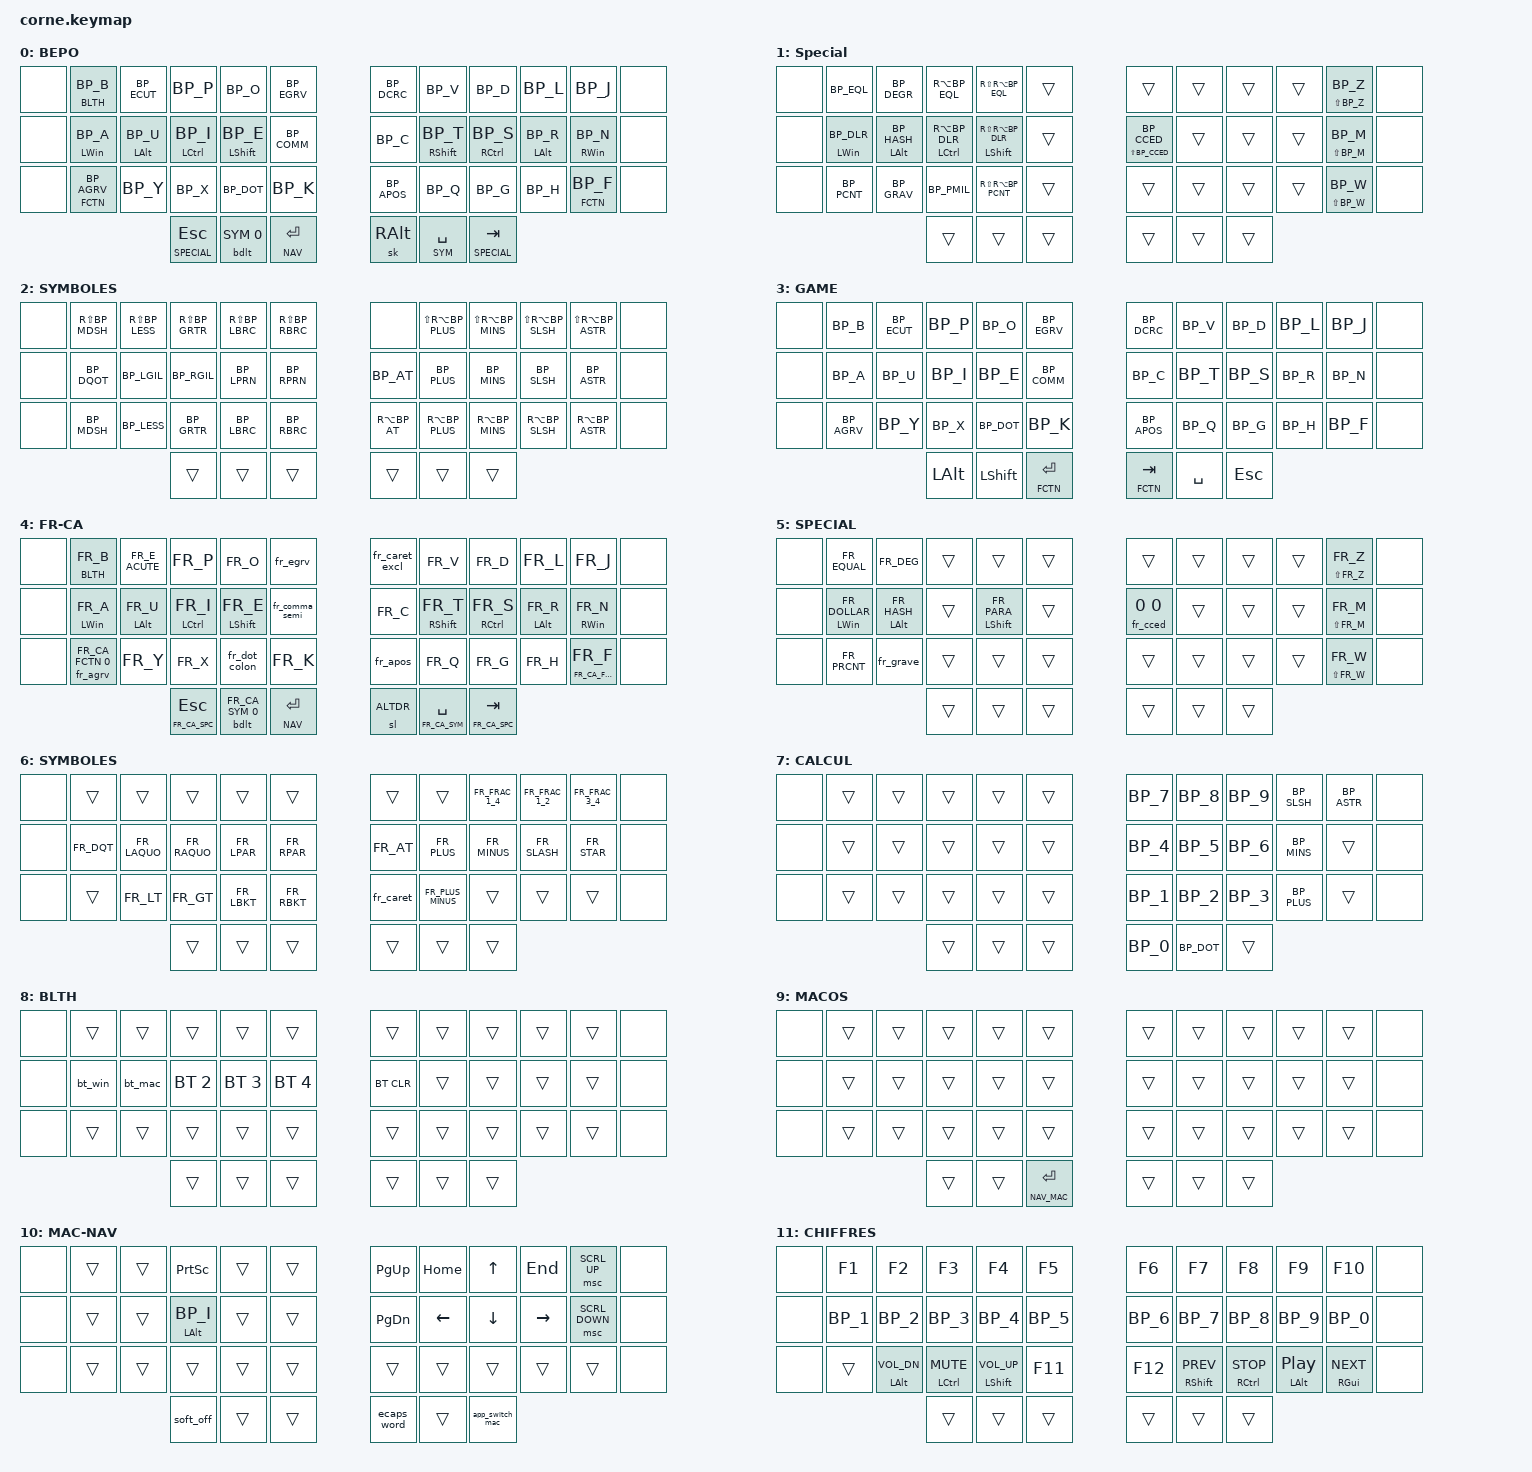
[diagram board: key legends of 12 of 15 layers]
/*
 * Corne 36-touches — ZMK — portage du layout BÉPO
 *
 *  ┌────┬────┬────┬────┬────┬────┐         ┌────┬────┬────┬────┬────┬────┐
 *  │ 0  │ 1  │ 2  │ 3  │ 4  │ 5  │         │ 6  │ 7  │ 8  │ 9  │ 10 │ 11 │
 *  ├────┼────┼────┼────┼────┼────┤         ├────┼────┼────┼────┼────┼────┤
 *  │ 12 │ 13 │ 14 │ 15 │ 16 │ 17 │         │ 18 │ 19 │ 20 │ 21 │ 22 │ 23 │
 *  ├────┼────┼────┼────┼────┼────┤         ├────┼────┼────┼────┼────┼────┤
 *  │ 24 │ 25 │ 26 │ 27 │ 28 │ 29 │         │ 30 │ 31 │ 32 │ 33 │ 34 │ 35 │
 *  └────┴────┴────┴─┬──┴─┬──┴─┬──┴─┐     ┌─┴──┬─┴──┬─┴──┬─┴────┴────┴────┘
 *                   │ 36 │ 37 │ 38 │     │ 39 │ 40 │ 41 │
 *                   └────┴────┴────┘     └────┴────┴────┘
 */

#include <behaviors.dtsi>
#include <dt-bindings/zmk/keys.h>
#include <dt-bindings/zmk/bt.h>
#include <dt-bindings/zmk/outputs.h>
#include <dt-bindings/zmk/pointing.h>
#include "keys_fr_csa.h"

/* ============================================================
 * LAYER NUMBERS
 * ============================================================ */
#define BEPO        0
#define SPECIAL     1
#define SYM         2
#define GAME        3
#define FR_CA       4
#define FR_CA_SPC   5
#define FR_CA_SYM   6
#define NUMPAD      7
#define BLTH        8
#define MACOS       9
#define NAV_MAC    10
#define FCTN       11
#define NAV        12
#define ALTDR      13
#define FR_CA_FCTN 14

/* ============================================================
 * BÉPO 
 * ============================================================ */
#define BP_B        Q
#define BP_ECUT     W
#define BP_W        RBKT
#define BP_P        E
#define BP_O        R
#define BP_EGRV     T
#define BP_A        A
#define BP_U        S
#define BP_I        D
#define BP_E        F
#define BP_COMM     G
#define BP_AGRV     Z
#define BP_Y        X
#define BP_X        C
#define BP_DOT      V
#define BP_K        B
#define BP_DCRC     Y
#define BP_V        U
#define BP_M        APOS
#define BP_D        I
#define BP_L        O
#define BP_J        P
#define BP_Z        LBKT
#define BP_C        H
#define BP_CCED     BACKSLASH
#define BP_T        J
#define BP_S        K
#define BP_R        L
#define BP_N        SEMI
#define BP_APOS     N
#define BP_Q        M
#define BP_G        COMMA
#define BP_H        DOT
#define BP_F        FSLH
#define BP_DQOT     N1
#define BP_DLR      GRAVE
#define BP_LGIL     N2
#define BP_RGIL     N3
#define BP_LPRN     N4
#define BP_RPRN     N5
#define BP_1        LS(N1)
#define BP_HASH     LS(GRAVE)
#define BP_2        LS(N2)
#define BP_3        LS(N3)
#define BP_4        LS(N4)
#define BP_5        LS(N5)
#define BP_MDSH     RA(N1)
#define BP_LESS     RA(N2)
#define BP_GRTR     RA(N3)
#define BP_LBRC     RA(N4)
#define BP_RBRC     RA(N5)
#define BP_AT       N6
#define BP_PLUS     N7
#define BP_MINS     N8
#define BP_SLSH     N9
#define BP_ASTR     N0
#define BP_EQL      MINUS
#define BP_6        LS(N6)
#define BP_7        LS(N7)
#define BP_8        LS(N8)
#define BP_9        LS(N9)
#define BP_0        LS(N0)
#define BP_DEGR     LS(MINUS)
#define BP_PCNT     EQUAL
#define BP_PMIL     RA(EQUAL)
#define BP_GRAV     LS(EQUAL)

#include "behaviors.dtsi"
#include "combos.dtsi"
#include "macros.dtsi"

/ {
    keymap {
        compatible = "zmk,keymap";

        layer_bepo { // Layer 0
                display-name = "BEPO";
        //  ┌──────────────────┬──────────────────┬──────────────────┬──────────────────┬──────────────────┬──────────────────┐                  ┌──────────────────┬──────────────────┬──────────────────┬──────────────────┬──────────────────┬──────────────────┐
        //  │                  │ B           BLTH │ É                │ P                │ O                │ È                │                  │ ^                │ V                │ D                │ L                │ J                │                  │
        //  ├──────────────────┼──────────────────┼──────────────────┼──────────────────┼──────────────────┼──────────────────┤                  ├──────────────────┼──────────────────┼──────────────────┼──────────────────┼──────────────────┼──────────────────┤
        //  │                  │ A           LWIN │ U           LALT │ I          LCTRL │ E         LSHIFT │ ,                │                  │ C                │ T         RSHIFT │ S          RCTRL │ R           LALT │ N           RWIN │                  │
        //  ├──────────────────┼──────────────────┼──────────────────┼──────────────────┼──────────────────┼──────────────────┤                  ├──────────────────┼──────────────────┼──────────────────┼──────────────────┼──────────────────┼──────────────────┤
        //  │                  │ À           FCTN │ Y                │ X                │ .                │ K                │                  │ ’                │ Q                │ G                │ H                │ F           FCTN │                  │
        //  └──────────────────┴──────────────────┴──────────────────┼──────────────────┼──────────────────┼──────────────────┤                  ├──────────────────┼──────────────────┼──────────────────┼──────────────────┴──────────────────┴──────────────────┘
        //                                                           │ ESC      SPECIAL │ BSPC         SYM │ ENTER        NAV │                  │ OSM RALT         │ SPACE        SYM │ TAB      SPECIAL │
        //                                                           └──────────────────┴──────────────────┴──────────────────┘                  └──────────────────┴──────────────────┴──────────────────┘
            bindings = <
                &none           &lt  BLTH  BP_B     &kp  BP_ECUT       &kp  BP_P         &kp   BP_O          &kp BP_EGRV                          &kp BP_DCRC         &kp  BP_V          &kp  BP_D          &kp  BP_L          &kp  BP_J          &none
                &none           &hml LWIN  BP_A     &hml LALT BP_U     &hml LCTRL BP_I   &hml  LSHFT  BP_E   &kp BP_COMM                          &kp BP_C            &hmr RSHFT BP_T    &hmr RCTRL BP_S    &hmr LALT BP_R     &hmr RWIN BP_N     &none
                &none           &lt  FCTN  BP_AGRV  &kp  BP_Y          &kp  BP_X         &kp   BP_DOT        &kp BP_K                             &kp BP_APOS         &kp  BP_Q          &kp  BP_G          &kp  BP_H          &lt  FCTN BP_F     &none
                                                                       &lt2 SPECIAL ESC    &bdlt SYM 0       &lt NAV ENTER                        &sk RALT            &lt  SYM   SPACE   &lt2 SPECIAL TAB
            >;
        };

        layer_special { // Layer 1
                display-name = "Special";
        //  ┌──────────────────┬──────────────────┬──────────────────┬──────────────────┬──────────────────┬──────────────────┐                  ┌──────────────────┬──────────────────┬──────────────────┬──────────────────┬──────────────────┬──────────────────┐
        //  │                  │ =                │ °                │ ≠                │ ′                │                  │                  │                  │                  │                  │                  │ Z                │                  │
        //  ├──────────────────┼──────────────────┼──────────────────┼──────────────────┼──────────────────┼──────────────────┤                  ├──────────────────┼──────────────────┼──────────────────┼──────────────────┼──────────────────┼──────────────────┤
        //  │                  │ $           LWIN │ #           LALT │ –          LCTRL │ ¶         LSHIFT │                  │                  │ Ç                │                  │                  │                  │ M                │                  │
        //  ├──────────────────┼──────────────────┼──────────────────┼──────────────────┼──────────────────┼──────────────────┤                  ├──────────────────┼──────────────────┼──────────────────┼──────────────────┼──────────────────┼──────────────────┤
        //  │                  │ %                │ `                │ ‰                │ ″                │                  │                  │                  │                  │                  │                  │ W                │                  │
        //  └──────────────────┴──────────────────┴──────────────────┼──────────────────┼──────────────────┼──────────────────┤                  ├──────────────────┼──────────────────┼──────────────────┼──────────────────┴──────────────────┴──────────────────┘
        //                                                           │                  │                  │                  │                  │                  │                  │                  │
        //                                                           └──────────────────┴──────────────────┴──────────────────┘                  └──────────────────┴──────────────────┴──────────────────┘
           bindings = <
                &none           &kp  BP_EQL          &kp  BP_DEGR      &kp RA(BP_EQL)        &kp  RS(RA(BP_EQL))        &trans                      &trans                   &trans      &trans             &trans             &mt LS(BP_Z) BP_Z  &none 
                &none           &hml LWIN BP_DLR     &hml LALT BP_HASH &hml LCTRL RA(BP_DLR) &hml LSHIFT RS(RA(BP_DLR)) &trans                      &mt LS(BP_CCED) BP_CCED  &trans      &trans             &trans             &mt LS(BP_M) BP_M  &none 
                &none           &kp  BP_PCNT         &kp  BP_GRAV      &kp BP_PMIL           &kp  RS(RA(BP_PCNT))       &trans                      &trans                   &trans      &trans             &trans             &mt LS(BP_W) BP_W  &none 
                                                                       &trans                &trans                     &trans                      &trans                   &trans      &trans
            >;

        };
        layer_sym { // Layer 2
                display-name = "SYMBOLES";
        //  ┌──────────────────┬──────────────────┬──────────────────┬──────────────────┬──────────────────┬──────────────────┐                  ┌──────────────────┬──────────────────┬──────────────────┬──────────────────┬──────────────────┬──────────────────┐
        //  │                  │ „                │ “                │ ”                │ ⩽                │ ⩾               │                  │                  │                  │ ¼                │ ½                │ ¾                │                  │
        //  ├──────────────────┼──────────────────┼──────────────────┼──────────────────┼──────────────────┼──────────────────┤                  ├──────────────────┼──────────────────┼──────────────────┼──────────────────┼──────────────────┼──────────────────┤
        //  │                  │ "                │ «                │ »                │ (                │ )                │                  │ @                │ +                │ -                │ /                │ *                │                  │                  │
        //  ├──────────────────┼──────────────────┼──────────────────┼──────────────────┼──────────────────┼──────────────────┤                  ├──────────────────┼──────────────────┼──────────────────┼──────────────────┼──────────────────┼──────────────────┤
        //  │                  │ —                │ <                │ >                │ [                │ ]                │                  │ ^                │ ±                │ −                │ ÷                │ ×                │                  │
        //  └──────────────────┴──────────────────┴──────────────────┼──────────────────┼──────────────────┼──────────────────┤                  ├──────────────────┼──────────────────┼──────────────────┼──────────────────┴──────────────────┴──────────────────┘
        //                                                           │                  │                  │                  │                  │                  │                  │                  │
        //                                                           └──────────────────┴──────────────────┴──────────────────┘                  └──────────────────┴──────────────────┴──────────────────┘
            bindings = <
                &none           &kp RS(BP_MDSH)     &kp RS(BP_LESS)   &kp RS(BP_GRTR)  &kp RS(BP_LBRC)    &kp RS(BP_RBRC)                          &none              &kp LS(RA(BP_PLUS)) &kp LS(RA(BP_MINS)) &kp LS(RA(BP_SLSH)) &kp LS(RA(BP_ASTR)) &none
                &none           &kp BP_DQOT         &kp BP_LGIL       &kp BP_RGIL      &kp BP_LPRN        &kp BP_RPRN                              &kp BP_AT          &kp BP_PLUS         &kp BP_MINS         &kp BP_SLSH         &kp BP_ASTR         &none
                &none           &kp BP_MDSH         &kp BP_LESS       &kp BP_GRTR      &kp BP_LBRC        &kp BP_RBRC                              &kp RA(BP_AT)      &kp RA(BP_PLUS)     &kp RA(BP_MINS)     &kp RA(BP_SLSH)     &kp RA(BP_ASTR)     &none
                                                                      &trans           &trans             &trans                                   &trans             &trans              &trans
            >;
        };

        layer_game { // Layer 3
                display-name = "GAME";
        //  ┌──────────────────┬──────────────────┬──────────────────┬──────────────────┬──────────────────┬──────────────────┐                  ┌──────────────────┬──────────────────┬──────────────────┬──────────────────┬──────────────────┬──────────────────┐
        //  │                  │ B                │ É                │ P                │ O                │ È                │                  │ ^                │ V                │ D                │ L                │ J                │                  │
        //  ├──────────────────┼──────────────────┼──────────────────┼──────────────────┼──────────────────┼──────────────────┤                  ├──────────────────┼──────────────────┼──────────────────┼──────────────────┼──────────────────┼──────────────────┤
        //  │                  │ A                │ U                │ I                │ E                │ ,                │                  │ C                │ T                │ S                │ R                │ N                │                  │
        //  ├──────────────────┼──────────────────┼──────────────────┼──────────────────┼──────────────────┼──────────────────┤                  ├──────────────────┼──────────────────┼──────────────────┼──────────────────┼──────────────────┼──────────────────┤
        //  │                  │ À                │ Y                │ X                │ .                │ K                │                  │ ’                │ Q                │ G                │ H                │ F                │                  │
        //  └──────────────────┴──────────────────┴──────────────────┼──────────────────┼──────────────────┼──────────────────┤                  ├──────────────────┼──────────────────┼──────────────────┼──────────────────┴──────────────────┴──────────────────┘
        //                                                           │ ESC              │ LSHIFT           │ ENTER            │                  │                  │                  │                  │
        //                                                           └──────────────────┴──────────────────┴──────────────────┘                  └──────────────────┴──────────────────┴──────────────────┘
            bindings = <
                &none           &kp  BP_B           &kp  BP_ECUT       &kp  BP_P         &kp  BP_O          &kp BP_EGRV                          &kp BP_DCRC         &kp  BP_V          &kp  BP_D          &kp  BP_L          &kp  BP_J          &none
                &none           &kp  BP_A           &kp  BP_U          &kp  BP_I         &kp  BP_E          &kp BP_COMM                          &kp BP_C            &kp  BP_T          &kp  BP_S          &kp  BP_R          &kp  BP_N          &none
                &none           &kp  BP_AGRV        &kp  BP_Y          &kp  BP_X         &kp  BP_DOT        &kp BP_K                             &kp BP_APOS         &kp  BP_Q          &kp  BP_G          &kp  BP_H          &kp  BP_F          &none
                                                                       &kp  LALT         &kp  LSHIFT        &lt FCTN ENTER                       &lt FCTN TAB        &kp  SPACE         &kp  ESC
            >;

        };

        layer_fr_ca { // Layer 4
                display-name = "FR-CA";
        //  ┌──────────────────┬──────────────────┬──────────────────┬──────────────────┬──────────────────┬──────────────────┐                  ┌──────────────────┬──────────────────┬──────────────────┬──────────────────┬──────────────────┬──────────────────┐
        //  │                  │ B           BLTH │ É                │ P                │ O                │ È                │                  │ ^                │ V                │ D                │ L                │ J                │                  │
        //  ├──────────────────┼──────────────────┼──────────────────┼──────────────────┼──────────────────┼──────────────────┤                  ├──────────────────┼──────────────────┼──────────────────┼──────────────────┼──────────────────┼──────────────────┤
        //  │                  │ A           LWIN │ U           LALT │ I          LCTRL │ E         LSHIFT │ ,                │                  │ C                │ T         RSHIFT │ S          RCTRL │ R           LALT │ N           RWIN │                  │
        //  ├──────────────────┼──────────────────┼──────────────────┼──────────────────┼──────────────────┼──────────────────┤                  ├──────────────────┼──────────────────┼──────────────────┼──────────────────┼──────────────────┼──────────────────┤
        //  │                  │ À           FCTN │ Y                │ X                │ .                │ K                │                  │ ’                │ Q                │ G                │ H                │ F           FCTN │                  │
        //  └──────────────────┴──────────────────┴──────────────────┼──────────────────┼──────────────────┼──────────────────┤                  ├──────────────────┼──────────────────┼──────────────────┼──────────────────┴──────────────────┴──────────────────┘
        //                                                           │ ESC    FR_CA_SPC │ BSPC         SYM │ ENTER        NAV │                  │ OSM RALT         │ SPACE        SYM │ TAB    FR_CA_SPC │
        //                                                           └──────────────────┴──────────────────┴──────────────────┘                  └──────────────────┴──────────────────┴──────────────────┘
            bindings = <
                &none           &lt  BLTH  FR_B     &kp  FR_E_ACUTE    &kp  FR_P            &kp  FR_O          &fr_egrv                           &fr_caret_excl     &kp  FR_V           &kp  FR_D          &kp  FR_L          &kp  FR_J           &none
                &none           &hml LWIN  FR_A     &hml LALT  FR_U    &hml LCTRL   FR_I    &hml LSHFT FR_E    &fr_comma_semi                     &kp  FR_C          &hmr RSHFT FR_T     &hmr RCTRL   FR_S  &hmr LALT  FR_R    &hmr RWIN  FR_N     &none
                &none           &fr_agrv FR_CA_FCTN 0 &kp  FR_Y       &kp  FR_X            &fr_dot_colon      &kp FR_K                           &fr_apos           &kp  FR_Q           &kp  FR_G          &kp  FR_H          &lt FR_CA_FCTN FR_F &none
                                                                       &lt2 FR_CA_SPC ESC   &bdlt FR_CA_SYM 0  &lt NAV ENTER                      &sl  ALTDR         &lt FR_CA_SYM SPACE &lt2 FR_CA_SPC TAB
            >;
        }; 

        layer_fr_ca_special { // Layer 5
                display-name = "SPECIAL";
        //  ┌──────────────────┬──────────────────┬──────────────────┬──────────────────┬──────────────────┬──────────────────┐                  ┌──────────────────┬──────────────────┬──────────────────┬──────────────────┬──────────────────┬──────────────────┐
        //  │                  │ =                │ °                │                  │                  │                  │                  │                  │                  │                  │                  │ Z                │                  │
        //  ├──────────────────┼──────────────────┼──────────────────┼──────────────────┼──────────────────┼──────────────────┤                  ├──────────────────┼──────────────────┼──────────────────┼──────────────────┼──────────────────┼──────────────────┤
        //  │                  │ $           LWIN │ #           LALT │                  │ ¶          LSHFT │                  │                  │ Ç                │                  │                  │                  │ M                │                  │
        //  ├──────────────────┼──────────────────┼──────────────────┼──────────────────┼──────────────────┼──────────────────┤                  ├──────────────────┼──────────────────┼──────────────────┼──────────────────┼──────────────────┼──────────────────┤
        //  │                  │ %                │ `                │                  │                  │                  │                  │                  │                  │                  │                  │ W                │                  │
        //  └──────────────────┴──────────────────┴──────────────────┼──────────────────┼──────────────────┼──────────────────┤                  ├──────────────────┼──────────────────┼──────────────────┼──────────────────┴──────────────────┴──────────────────┘
        //                                                           │                  │                  │                  │                  │                  │                  │                  │
        //                                                           └──────────────────┴──────────────────┴──────────────────┘                  └──────────────────┴──────────────────┴──────────────────┘
           bindings = <
                &none           &kp  FR_EQUAL        &kp  FR_DEG        &trans            &trans               &trans                             &trans                &trans             &trans             &trans             &mt LS(FR_Z) FR_Z   &none 
                &none           &hml LWIN FR_DOLLAR  &hml LALT FR_HASH  &trans            &hml LSHIFT FR_PARA  &trans                             &fr_cced 0 0          &trans             &trans             &trans             &mt LS(FR_M) FR_M   &none
                &none           &kp  FR_PRCNT        &fr_grave          &trans            &trans               &trans                             &trans                &trans             &trans             &trans             &mt LS(FR_W) FR_W   &none 
                                                                        &trans            &trans               &trans                             &trans                &trans             &trans
            >;
        };

        layer_fr_ca_sym { // Layer 6
                display-name = "SYMBOLES";
        //  ┌──────────────────┬──────────────────┬──────────────────┬──────────────────┬──────────────────┬──────────────────┐                  ┌──────────────────┬──────────────────┬──────────────────┬──────────────────┬──────────────────┬──────────────────┐
        //  │                  │                  │                  │                  │                  │                  │                  │                  │                  │ ¼                │ ½                │ ¾                │                  │
        //  ├──────────────────┼──────────────────┼──────────────────┼──────────────────┼──────────────────┼──────────────────┤                  ├──────────────────┼──────────────────┼──────────────────┼──────────────────┼──────────────────┼──────────────────┤
        //  │                  │ "                │ «                │ »                │ (                │ )                │                  │ @                │ +                │ -                │ /                │ *                │                  │                  │
        //  ├──────────────────┼──────────────────┼──────────────────┼──────────────────┼──────────────────┼──────────────────┤                  ├──────────────────┼──────────────────┼──────────────────┼──────────────────┼──────────────────┼──────────────────┤
        //  │                  │                  │ <                │ >                │ [                │ ]                │                  │ ^                │ ±                │                  │                  │                  │                  │
        //  └──────────────────┴──────────────────┴──────────────────┼──────────────────┼──────────────────┼──────────────────┤                  ├──────────────────┼──────────────────┼──────────────────┼──────────────────┴──────────────────┴──────────────────┘
        //                                                           │                  │                  │                  │                  │                  │                  │                  │
        //                                                           └──────────────────┴──────────────────┴──────────────────┘                  └──────────────────┴──────────────────┴──────────────────┘
            bindings = <
                &none           &trans              &trans            &trans           &trans             &trans                                   &trans             &trans              &kp FR_FRAC_1_4     &kp FR_FRAC_1_2     &kp FR_FRAC_3_4     &none
                &none           &kp FR_DQT          &kp FR_LAQUO      &kp FR_RAQUO     &kp FR_LPAR        &kp FR_RPAR                              &kp FR_AT          &kp FR_PLUS         &kp FR_MINUS        &kp FR_SLASH        &kp FR_STAR         &none
                &none           &trans              &kp FR_LT         &kp FR_GT        &kp FR_LBKT        &kp FR_RBKT                              &fr_caret          &kp FR_PLUS_MINUS   &trans              &trans              &trans              &none
                                                                      &trans           &trans             &trans                                   &trans             &trans              &trans
            >;
        };

        layer_numpad { // Layer 7
                display-name = "CALCUL";
        //  ┌──────────────────┬──────────────────┬──────────────────┬──────────────────┬──────────────────┬──────────────────┐                  ┌──────────────────┬──────────────────┬──────────────────┬──────────────────┬──────────────────┬──────────────────┐
        //  │                  │                  │                  │                  │                  │                  │                  │ 7                │ 8                │ 9                │ /                │ *                │                  │
        //  ├──────────────────┼──────────────────┼──────────────────┼──────────────────┼──────────────────┼──────────────────┤                  ├──────────────────┼──────────────────┼──────────────────┼──────────────────┼──────────────────┼──────────────────┤
        //  │                  │                  │                  │                  │                  │                  │                  │ 4                │ 5                │ 6                │ -                │                  │                  │
        //  ├──────────────────┼──────────────────┼──────────────────┼──────────────────┼──────────────────┼──────────────────┤                  ├──────────────────┼──────────────────┼──────────────────┼──────────────────┼──────────────────┼──────────────────┤
        //  │                  │                  │                  │                  │                  │                  │                  │ 1                │ 2                │ 3                │ +                │                  │                  │
        //  └──────────────────┴──────────────────┴──────────────────┼──────────────────┼──────────────────┼──────────────────┤                  ├──────────────────┼──────────────────┼──────────────────┼──────────────────┴──────────────────┴──────────────────┘
        //                                                           │                  │                  │                  │                  │ 0                │ .                │                  │
        //                                                           └──────────────────┴──────────────────┴──────────────────┘                  └──────────────────┴──────────────────┴──────────────────┘
           bindings = <
                &none           &trans                    &trans            &trans           &trans             &trans                            &kp BP_7            &kp BP_8           &kp BP_9           &kp BP_SLSH        &kp BP_ASTR        &none
                &none           &trans                    &trans            &trans           &trans             &trans                            &kp BP_4            &kp BP_5           &kp BP_6           &kp BP_MINS        &trans             &none
                &none           &trans                    &trans            &trans           &trans             &trans                            &kp BP_1            &kp BP_2           &kp BP_3           &kp BP_PLUS        &trans             &none
                                                                            &trans           &trans             &trans                            &kp BP_0            &kp BP_DOT         &trans
            >;
        };
        
        layer_bluetooth { // Layer 8
                display-name = "BLTH";
        //  ┌──────────────────┬──────────────────┬──────────────────┬──────────────────┬──────────────────┬──────────────────┐                  ┌──────────────────┬──────────────────┬──────────────────┬──────────────────┬──────────────────┬──────────────────┐
        //  │                  │                  │                  │                  │                  │                  │                  │                  │                  │                  │                  │                  │                  │
        //  ├──────────────────┼──────────────────┼──────────────────┼──────────────────┼──────────────────┼──────────────────┤                  ├──────────────────┼──────────────────┼──────────────────┼──────────────────┼──────────────────┼──────────────────┤
        //  │                  │ CHANNEL 0        │ CHANNEL 1        │ CHANNEL 2        │ CHANNEL 3        │ CHANNEL 4        │                  │ BT_CLR           │                  │                  │                  │                  │                  │
        //  ├──────────────────┼──────────────────┼──────────────────┼──────────────────┼──────────────────┼──────────────────┤                  ├──────────────────┼──────────────────┼──────────────────┼──────────────────┼──────────────────┼──────────────────┤
        //  │                  │                  │                  │                  │                  │                  │                  │                  │                  │                  │                  │                  │                  │
        //  └──────────────────┴──────────────────┴──────────────────┼──────────────────┼──────────────────┼──────────────────┤                  ├──────────────────┼──────────────────┼──────────────────┼──────────────────┴──────────────────┴──────────────────┘
        //                                                           │                  │                  │                  │                  │                  │                  │                  │
        //                                                           └──────────────────┴──────────────────┴──────────────────┘                  └──────────────────┴──────────────────┴──────────────────┘
           bindings = <
                &none           &trans                    &trans            &trans           &trans             &trans                          &trans                      &trans            &trans           &trans          &trans    &none 
                &none           &bt_win                   &bt_mac           &bt BT_SEL 2     &bt BT_SEL 3       &bt BT_SEL 4                    &bt BT_CLR                  &trans            &trans           &trans          &trans    &none 
                &none           &trans                    &trans            &trans           &trans             &trans                          &trans                      &trans            &trans           &trans          &trans    &none 
                                                                            &trans           &trans             &trans                          &trans                      &trans            &trans
            >;
        };

        layer_mac_os { // Layer 9
                display-name = "MACOS";
        //  ┌──────────────────┬──────────────────┬──────────────────┬──────────────────┬──────────────────┬──────────────────┐                  ┌──────────────────┬──────────────────┬──────────────────┬──────────────────┬──────────────────┬──────────────────┐
        //  │                  │                  │                  │                  │                  │                  │                  │                  │                  │                  │                  │                  │                  │
        //  ├──────────────────┼──────────────────┼──────────────────┼──────────────────┼──────────────────┼──────────────────┤                  ├──────────────────┼──────────────────┼──────────────────┼──────────────────┼──────────────────┼──────────────────┤
        //  │                  │                  │                  │                  │                  │                  │                  │                  │                  │                  │                  │                  │                  │
        //  ├──────────────────┼──────────────────┼──────────────────┼──────────────────┼──────────────────┼──────────────────┤                  ├──────────────────┼──────────────────┼──────────────────┼──────────────────┼──────────────────┼──────────────────┤
        //  │                  │                  │                  │                  │                  │                  │                  │                  │                  │                  │                  │                  │                  │
        //  └──────────────────┴──────────────────┴──────────────────┼──────────────────┼──────────────────┼──────────────────┤                  ├──────────────────┼──────────────────┼──────────────────┼──────────────────┴──────────────────┴──────────────────┘
        //                                                           │                  │                  │ ENTER    NAV_MAC │                  │                  │                  │                  │
        //                                                           └──────────────────┴──────────────────┴──────────────────┘                  └──────────────────┴──────────────────┴──────────────────┘
            bindings = <
                &none           &trans                    &trans            &trans          &trans             &trans                              &trans              &trans            &trans           &trans          &trans    &none 
                &none           &trans                    &trans            &trans          &trans             &trans                              &trans              &trans            &trans           &trans          &trans    &none 
                &none           &trans                    &trans            &trans          &trans             &trans                              &trans              &trans            &trans           &trans          &trans    &none 
                                                                            &trans          &trans             &lt NAV_MAC ENTER                   &trans              &trans            &trans
            >;
        };

        layer_nav_mac { // Layer 10
                display-name = "MAC-NAV";
        //  ┌──────────────────┬──────────────────┬──────────────────┬──────────────────┬──────────────────┬──────────────────┐                  ┌──────────────────┬──────────────────┬──────────────────┬──────────────────┬──────────────────┬──────────────────┐
        //  │                  │                  │                  │ PRINTSCREEN      │                  │                  │                  │ PGUP             │ HOME             │ UP               │ END              │ SCROLL UP        │                  │
        //  ├──────────────────┼──────────────────┼──────────────────┼──────────────────┼──────────────────┼──────────────────┤                  ├──────────────────┼──────────────────┼──────────────────┼──────────────────┼──────────────────┼──────────────────┤
        //  │                  │                  │                  │                  │                  │                  │                  │ PGDOWN           │ LEFT             │ DOWN             │ RIGHT            │ SCROLL DOWN      │                  │
        //  ├──────────────────┼──────────────────┼──────────────────┼──────────────────┼──────────────────┼──────────────────┤                  ├──────────────────┼──────────────────┼──────────────────┼──────────────────┼──────────────────┼──────────────────┤
        //  │                  │                  │                  │                  │                  │                  │                  │                  │                  │                  │                  │                  │                  │
        //  └──────────────────┴──────────────────┴──────────────────┼──────────────────┼──────────────────┼──────────────────┤                  ├──────────────────┼──────────────────┼──────────────────┼──────────────────┴──────────────────┴──────────────────┘
        //                                                           │ SOFT OFF         │                  │                  │                  │ CAPS WORD        │                  │                  │
        //                                                           └──────────────────┴──────────────────┴──────────────────┘                  └──────────────────┴──────────────────┴──────────────────┘
            bindings = <
                &none           &trans             &trans              &kp PSCRN          &trans             &trans                               &kp PG_UP           &kp HOME          &kp UP              &kp END            &msc SCRL_UP      &none
                &none           &trans             &trans              &hml LALT BP_I     &trans             &trans                               &kp PG_DN           &kp LEFT          &kp DOWN            &kp RIGHT          &msc SCRL_DOWN    &none
                &none           &trans             &trans              &trans             &trans             &trans                               &trans              &trans            &trans              &trans             &trans            &none
                                                                       &soft_off          &trans             &trans                               &ecaps_word         &trans            &app_switch_mac
            >;
         };

       layer_fun { // Layer 11
                display-name = "CHIFFRES";
        //  ┌──────────────────┬──────────────────┬──────────────────┬──────────────────┬──────────────────┬──────────────────┐                  ┌──────────────────┬──────────────────┬──────────────────┬──────────────────┬──────────────────┬──────────────────┐
        //  │                  │ F1               │ F2               │ F3               │ F4               │ F5               │                  │ F6               │ F7               │ F8               │ F9               │ F10              │                  │
        //  ├──────────────────┼──────────────────┼──────────────────┼──────────────────┼──────────────────┼──────────────────┤                  ├──────────────────┼──────────────────┼──────────────────┼──────────────────┼──────────────────┼──────────────────┤
        //  │                  │ 1                │ 2                │ 3                │ 4                │ 5                │                  │ 6                │ 7                │ 8                │ 9                │ 0                │                  │
        //  ├──────────────────┼──────────────────┼──────────────────┼──────────────────┼──────────────────┼──────────────────┤                  ├──────────────────┼──────────────────┼──────────────────┼──────────────────┼──────────────────┼──────────────────┤
        //  │                  │                  │ VOL-        LALT │ MUTE       LCTRL │ VOL+      LSHIFT │ F11              │                  │ F12              │ PREV      RSHIFT │ STOP       RCTRL │ PLAY        LALT │ NEXT        RWIN │                  │
        //  └──────────────────┴──────────────────┴──────────────────┼──────────────────┼──────────────────┼──────────────────┤                  ├──────────────────┼──────────────────┼──────────────────┼──────────────────┴──────────────────┴──────────────────┘
        //                                                           │                  │                  │                  │                  │                  │                  │                  │
        //                                                           └──────────────────┴──────────────────┴──────────────────┘                  └──────────────────┴──────────────────┴──────────────────┘
            bindings = <
                &none           &kp F1              &kp F2             &kp F3             &kp F4             &kp F5                                &kp F6             &kp F7            &kp F8           &kp F9          &kp F10            &none
                &none           &kp BP_1            &kp BP_2           &kp BP_3           &kp BP_4           &kp BP_5                              &kp BP_6           &kp BP_7          &kp BP_8         &kp BP_9        &kp BP_0           &none
                &none           &trans              &mt LALT C_VOL_DN  &mt LCTRL C_MUTE   &mt LSHFT C_VOL_UP &kp F11                               &kp F12            &mt RSHFT C_PREV  &mt RCTRL C_STOP &mt LALT C_PP   &mt RGUI C_NEXT    &none
                                                                       &trans             &trans             &trans                                &trans             &trans            &trans
            >;
        };

        layer_nav { // Layer 12
                display-name = "NAV";
        //  ┌──────────────────┬──────────────────┬──────────────────┬──────────────────┬──────────────────┬──────────────────┐                  ┌──────────────────┬──────────────────┬──────────────────┬──────────────────┬──────────────────┬──────────────────┐
        //  │                  │                  │                  │ PRINTSCREEN      │                  │                  │                  │ PGUP             │ HOME             │ UP               │ END              │ SCROLL UP        │                  │
        //  ├──────────────────┼──────────────────┼──────────────────┼──────────────────┼──────────────────┼──────────────────┤                  ├──────────────────┼──────────────────┼──────────────────┼──────────────────┼──────────────────┼──────────────────┤
        //  │                  │                  │                  │                  │                  │                  │                  │ PGDOWN           │ LEFT             │ DOWN             │ RIGHT            │ SCROLL DOWN      │                  │
        //  ├──────────────────┼──────────────────┼──────────────────┼──────────────────┼──────────────────┼──────────────────┤                  ├──────────────────┼──────────────────┼──────────────────┼──────────────────┼──────────────────┼──────────────────┤
        //  │                  │                  │                  │                  │                  │                  │                  │                  │                  │                  │                  │                  │                  │
        //  └──────────────────┴──────────────────┴──────────────────┼──────────────────┼──────────────────┼──────────────────┤                  ├──────────────────┼──────────────────┼──────────────────┼──────────────────┴──────────────────┴──────────────────┘
        //                                                           │ SOFT OFF         │                  │                  │                  │ CAPS WORD        │                  │                  │
        //                                                           └──────────────────┴──────────────────┴──────────────────┘                  └──────────────────┴──────────────────┴──────────────────┘
            bindings = <
                &none           &trans                    &trans            &kp PSCRN        &trans             &trans                          &kp PG_UP                   &kp HOME          &kp UP           &kp END         &msc SCRL_UP      &none
                &none           &trans                    &trans            &trans           &trans             &trans                          &kp PG_DN                   &kp LEFT          &kp DOWN         &kp RIGHT       &msc SCRL_DOWN    &none
                &none           &trans                    &trans            &trans           &trans             &trans                          &trans                      &trans            &trans           &trans          &trans            &none
                                                                            &soft_off        &trans             &trans                          &ecaps_word                 &trans            &app_switch
            >;
         };

        layer_mac_altdr { // Layer 13
                display-name = "MACOS";
        //  ┌──────────────────┬──────────────────┬──────────────────┬──────────────────┬──────────────────┬──────────────────┐                  ┌──────────────────┬──────────────────┬──────────────────┬──────────────────┬──────────────────┬──────────────────┐
        //  │                  │ |                │ ´                │ &                │                  │ `                │                  │                  │                  │                  │                  │                  │                  │
        //  ├──────────────────┼──────────────────┼──────────────────┼──────────────────┼──────────────────┼──────────────────┤                  ├──────────────────┼──────────────────┼──────────────────┼──────────────────┼──────────────────┼──────────────────┤
        //  │                  │                  │ ù                │ ¨                │                  │ '                │                  │                  │                  │                  │                  │                  │                  │
        //  ├──────────────────┼──────────────────┼──────────────────┼──────────────────┼──────────────────┼──────────────────┤                  ├──────────────────┼──────────────────┼──────────────────┼──────────────────┼──────────────────┼──────────────────┤
        //  │                  │ \                │ {                │ }                │ …                │ ~                │                  │                  │                  │ µ                │                  │                  │                  │
        //  └──────────────────┴──────────────────┴──────────────────┼──────────────────┼──────────────────┼──────────────────┤                  ├──────────────────┼──────────────────┼──────────────────┼──────────────────┴──────────────────┴──────────────────┘
        //                                                           │                  │                  │                  │                  │                  │ _                │                  │
        //                                                           └──────────────────┴──────────────────┴──────────────────┘                  └──────────────────┴──────────────────┴──────────────────┘
            bindings = <
                &none           &kp FR_PIPE        &kp FR_ACUTE        &kp FR_AMPS        &trans             &kp FR_GRAVE                          &trans             &trans             &trans             &trans             &trans             &none 
                &none           &trans             &fr_u_grave         &kp FR_UMLAUT      &trans             &kp FR_APOS                           &trans             &trans             &trans             &trans             &trans             &none 
                &none           &kp FR_BSLH        &kp FR_LBRC         &kp FR_RBRC        &fr_sspnsn         &kp FR_TILDE                          &trans             &trans             &kp FR_MU          &trans             &trans             &none 
                                                                       &trans             &trans             &trans                                &trans             &kp FR_UNDER       &trans 
            >;
        };

       layer_fr_ca_fun { // Layer 14
                display-name = "CHIFFRES";
        //  ┌──────────────────┬──────────────────┬──────────────────┬──────────────────┬──────────────────┬──────────────────┐                  ┌──────────────────┬──────────────────┬──────────────────┬──────────────────┬──────────────────┬──────────────────┐
        //  │                  │ F1               │ F2               │ F3               │ F4               │ F5               │                  │ F6               │ F7               │ F8               │ F9               │ F10              │                  │
        //  ├──────────────────┼──────────────────┼──────────────────┼──────────────────┼──────────────────┼──────────────────┤                  ├──────────────────┼──────────────────┼──────────────────┼──────────────────┼──────────────────┼──────────────────┤
        //  │                  │ 1                │ 2                │ 3                │ 4                │ 5                │                  │ 6                │ 7                │ 8                │ 9                │ 0                │                  │
        //  ├──────────────────┼──────────────────┼──────────────────┼──────────────────┼──────────────────┼──────────────────┤                  ├──────────────────┼──────────────────┼──────────────────┼──────────────────┼──────────────────┼──────────────────┤
        //  │                  │                  │ VOL-        LALT │ MUTE       LCTRL │ VOL+      LSHIFT │ F11              │                  │ F12              │ PREV      RSHIFT │ STOP       RCTRL │ PLAY        LALT │ NEXT        RWIN │                  │
        //  └──────────────────┴──────────────────┴──────────────────┼──────────────────┼──────────────────┼──────────────────┤                  ├──────────────────┼──────────────────┼──────────────────┼──────────────────┴──────────────────┴──────────────────┘
        //                                                           │                  │                  │                  │                  │                  │                  │                  │
        //                                                           └──────────────────┴──────────────────┴──────────────────┘                  └──────────────────┴──────────────────┴──────────────────┘
            bindings = <
                &none           &kp F1              &kp F2             &kp F3             &kp F4             &kp F5                                &kp F6             &kp F7            &kp F8             &kp F9             &kp F10            &none
                &none           &kp FR_N1           &kp FR_N2          &kp FR_N3          &kp FR_N4          &kp FR_N5                             &kp FR_N6          &kp FR_N7         &kp FR_N8          &kp FR_N9          &kp FR_N0          &none
                &none           &trans              &mt LALT C_VOL_DN  &mt LCTRL C_MUTE   &mt LSHFT C_VOL_UP &kp F11                               &kp F12            &mt RSHFT C_PREV  &mt RCTRL C_STOP   &mt LALT C_PP      &mt RGUI C_NEXT    &none
                                                                       &trans             &trans             &trans                                &trans             &trans            &trans
            >;
        };

    };
};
